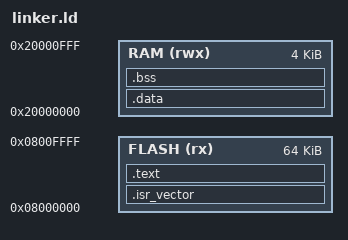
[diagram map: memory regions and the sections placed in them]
ENTRY(Reset_Handler)

MEMORY
{
    FLASH (rx)  : ORIGIN = 0x08000000, LENGTH = 64K
    RAM   (rwx) : ORIGIN = 0x20000000, LENGTH = 4K
}

_estack = ORIGIN(RAM) + LENGTH(RAM);

SECTIONS
{
    .isr_vector :
    {
        KEEP(*(.isr_vector))
    } > FLASH

    .text :
    {
        *(.text.Reset_Handler)
        *(.text*)
        *(.rodata*)
        *(.glue_7)
        *(.glue_7t)
        _etext = .;
    } > FLASH

    .data : AT(_etext)
    {
        _sdata = .;
        *(.data*)
        _edata = .;
    } > RAM

    .bss (NOLOAD) :
    {
        _sbss = .;
        *(.bss*)
        *(COMMON)
        _ebss = .;
    } > RAM

    /DISCARD/ :
    {
        *(.note*)
        *(.comment*)
    }
}
